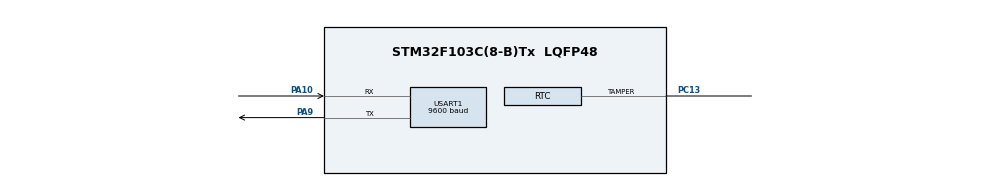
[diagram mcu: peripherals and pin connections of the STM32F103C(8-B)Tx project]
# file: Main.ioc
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Mcu.Family=STM32F1
Mcu.Name=STM32F103C(8-B)Tx
Mcu.Package=LQFP48
NVIC.PriorityGroup=NVIC_PRIORITYGROUP_4
NVIC.RTC_IRQn=true\:0\:0\:false\:false\:true\:true\:true\:true
NVIC.TAMPER_IRQn=true\:0\:0\:false\:false\:true\:true\:true\:true
PA10.Mode=Asynchronous
PA10.Signal=USART1_RX
PA13.Mode=Serial_Wire
PA13.Signal=SYS_JTMS-SWDIO
PA14.Mode=Serial_Wire
PA14.Signal=SYS_JTCK-SWCLK
PA9.Mode=Asynchronous
PA9.Signal=USART1_TX
PC13-TAMPER-RTC.Mode=Tamper
PC13-TAMPER-RTC.Signal=RTC_TAMPER
PC14-OSC32_IN.Mode=LSE-External-Oscillator
PC14-OSC32_IN.Signal=RCC_OSC32_IN
PC15-OSC32_OUT.Mode=LSE-External-Oscillator
PC15-OSC32_OUT.Signal=RCC_OSC32_OUT
ProjectManager.HeapSize=0x200
ProjectManager.StackSize=0x400
ProjectManager.TargetToolchain=MDK-ARM V5.32
RCC.AHBFreq_Value=8000000
RCC.APB1Freq_Value=8000000
RCC.APB1TimFreq_Value=8000000
RCC.APB2Freq_Value=8000000
RCC.APB2TimFreq_Value=8000000
RCC.HCLKFreq_Value=8000000
RCC.PLLMUL=RCC_PLL_MUL9
RCC.RTCClockSelection=RCC_RTCCLKSOURCE_LSE
RCC.SYSCLKFreq_VALUE=8000000
RCC.USBFreq_Value=36000000
RTC.AutoPrediv=RTC_AUTO_1_SECOND
RTC.Format=RTC_FORMAT_BIN
RTC.OutPut=RTC_OUTPUTSOURCE_NONE
USART1.BaudRate=9600
USART1.VirtualMode=VM_ASYNC
VP_RTC_VS_RTC_Activate.Mode=RTC_Enabled
VP_RTC_VS_RTC_Calendar.Mode=RTC_Calendar
board=custom

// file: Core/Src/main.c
/* USER CODE BEGIN Header */
/**
  ******************************************************************************
  * @file           : main.c
  * @brief          : Main program body
  ******************************************************************************
  * @attention
  *
  * <h2><center>&copy; Copyright (c) 2021 STMicroelectronics.
  * All rights reserved.</center></h2>
  *
  * This software component is licensed by ST under BSD 3-Clause license,
  * the "License"; You may not use this file except in compliance with the
  * License. You may obtain a copy of the License at:
  *                        opensource.org/licenses/BSD-3-Clause
  *
  ******************************************************************************
  */
/* USER CODE END Header */
#include "main.h"

/* USER CODE BEGIN Includes */
#include "stdio.h"
/* USER CODE END Includes */

/* USER CODE BEGIN PV */
uint32_t buffer=0;
/* USER CODE END PV */

void SystemClock_Config(void);
static void MX_GPIO_Init(void);
static void MX_RTC_Init(void);
static void MX_USART1_UART_Init(void);

/* USER CODE BEGIN 0 */
/* Function for transmitting 8bit data via USART */
void write_uart(char data){
	while(!LL_USART_IsActiveFlag_TXE(USART1));
	LL_USART_TransmitData8(USART1, (uint8_t)data);
}

/* Retargeting stdout_putchar as to use USART_TX for data output */
int stdout_putchar(int ch){
	write_uart(ch);
	return (ch);
}

struct time_t
{
  uint8_t sec;
  uint8_t min;
  uint8_t hour;
};

struct time_t Time;
struct time_t Alarm;

uint32_t TimeCounter = 0;

void TIME_Update(void);
void TIME_Config(uint8_t, uint8_t, uint8_t);
void ALARM_Config(uint8_t, uint8_t, uint8_t);
/* USER CODE END 0 */

int main(void)
{

  /* MCU Configuration--------------------------------------------------------*/

  /* Reset of all peripherals, Initializes the Flash interface and the Systick. */
  LL_APB2_GRP1_EnableClock(LL_APB2_GRP1_PERIPH_AFIO);
  LL_APB1_GRP1_EnableClock(LL_APB1_GRP1_PERIPH_PWR);

  /* System interrupt init*/
  NVIC_SetPriorityGrouping(NVIC_PRIORITYGROUP_4);

  /** NOJTAG: JTAG-DP Disabled and SW-DP Enabled
  */
  LL_GPIO_AF_Remap_SWJ_NOJTAG();

  /* Configure the system clock */
  SystemClock_Config();

  /* Initialize all configured peripherals */
  MX_GPIO_Init();
  MX_RTC_Init();
  MX_USART1_UART_Init();
	printf("TEST USART1 \r\n");
  /* USER CODE BEGIN 2 */
  /* configue date, time and alarm and also enabling alarm interrupt */
	LL_RTC_DisableWriteProtection(RTC);
  LL_RTC_EnterInitMode(RTC);
	LL_RTC_EnableIT_ALR(RTC);
	LL_RTC_ClearFlag_ALR(RTC);
//	LL_EXTI_EnableIT_0_31(LL_EXTI_LINE_17);
//	LL_EXTI_EnableRisingTrig_0_31(LL_EXTI_LINE_17);
//
	LL_RTC_ExitInitMode(RTC);
	LL_RTC_EnableWriteProtection(RTC);
  /* USER CODE END 2 */

  /* Infinite loop */
  /* USER CODE BEGIN WHILE */

	TIME_Config(23, 59, 55);
	ALARM_Config(00, 00, 05);

	//printf("GetRTCClockSource: %.2d\r\n", buffer);

  while(1){
    /* USER CODE END WHILE */

    /* USER CODE BEGIN 3 */
		/* update and print date and time */
		for(int i=0; i<10; i++){
			TIME_Update();
			printf("Time: %.2d:%.2d:%.2d\r\n", Time.hour, Time.min, Time.sec);
			LL_mDelay(998);
		}
  }
  /* USER CODE END 3 */
}

void SystemClock_Config(void)
{
  LL_FLASH_SetLatency(LL_FLASH_LATENCY_0);
  while(LL_FLASH_GetLatency()!= LL_FLASH_LATENCY_0)
  {
  }
  LL_RCC_HSI_SetCalibTrimming(16);
  LL_RCC_HSI_Enable();

   /* Wait till HSI is ready */
  while(LL_RCC_HSI_IsReady() != 1)
  {

  }
  LL_PWR_EnableBkUpAccess();
  if(LL_RCC_GetRTCClockSource() != LL_RCC_RTC_CLKSOURCE_LSE)
  {
    LL_RCC_ForceBackupDomainReset();
    LL_RCC_ReleaseBackupDomainReset();
  }
  LL_RCC_LSE_Enable();

   /* Wait till LSE is ready */
  while(LL_RCC_LSE_IsReady() != 1)
  {

  }
  if(LL_RCC_GetRTCClockSource() != LL_RCC_RTC_CLKSOURCE_LSE)
  {
    LL_RCC_SetRTCClockSource(LL_RCC_RTC_CLKSOURCE_LSE);
  }
  LL_RCC_EnableRTC();
  LL_RCC_SetAHBPrescaler(LL_RCC_SYSCLK_DIV_1);
  LL_RCC_SetAPB1Prescaler(LL_RCC_APB1_DIV_1);
  LL_RCC_SetAPB2Prescaler(LL_RCC_APB2_DIV_1);
  LL_RCC_SetSysClkSource(LL_RCC_SYS_CLKSOURCE_HSI);

   /* Wait till System clock is ready */
  while(LL_RCC_GetSysClkSource() != LL_RCC_SYS_CLKSOURCE_STATUS_HSI)
  {

  }
  LL_Init1msTick(8000000);
  LL_SetSystemCoreClock(8000000);
}

static void MX_RTC_Init(void)
{

  LL_RTC_InitTypeDef RTC_InitStruct = {0};
  LL_RTC_TimeTypeDef RTC_TimeStruct = {0};

    LL_PWR_EnableBkUpAccess();
    /* Enable BKP CLK enable for backup registers */
    LL_APB1_GRP1_EnableClock(LL_APB1_GRP1_PERIPH_BKP);
  /* Peripheral clock enable */
  LL_RCC_EnableRTC();

  /* RTC interrupt Init */
  NVIC_SetPriority(TAMPER_IRQn, NVIC_EncodePriority(NVIC_GetPriorityGrouping(),0, 0));
  NVIC_EnableIRQ(TAMPER_IRQn);
  NVIC_SetPriority(RTC_IRQn, NVIC_EncodePriority(NVIC_GetPriorityGrouping(),0, 0));
  NVIC_EnableIRQ(RTC_IRQn);

  /** Initialize RTC and set the Time and Date
  */
  RTC_InitStruct.AsynchPrescaler = 0xFFFFFFFFU;
  LL_RTC_Init(RTC, &RTC_InitStruct);
  LL_RTC_SetAsynchPrescaler(RTC, 0xFFFFFFFFU);

  /** Initialize RTC and set the Time and Date
  */
  RTC_TimeStruct.Hours = 0;
  RTC_TimeStruct.Minutes = 0;
  RTC_TimeStruct.Seconds = 0;
  LL_RTC_TIME_Init(RTC, LL_RTC_FORMAT_BIN, &RTC_TimeStruct);

  /** Initialize RTC and set the Time and Date
  */
  /* USER CODE BEGIN RTC_Init 2 */
  /* set RTC clock prescaler to 32768 (8000-1 hex)*/
  RTC_InitStruct.AsynchPrescaler = 0x00007FFFU;
  LL_RTC_Init(RTC, &RTC_InitStruct);
  LL_RTC_SetAsynchPrescaler(RTC, 0x00007FFFU);
  /* USER CODE END RTC_Init 2 */

}

static void MX_USART1_UART_Init(void)
{

  LL_USART_InitTypeDef USART_InitStruct = {0};

  LL_GPIO_InitTypeDef GPIO_InitStruct = {0};

  /* Peripheral clock enable */
  LL_APB2_GRP1_EnableClock(LL_APB2_GRP1_PERIPH_USART1);

  LL_APB2_GRP1_EnableClock(LL_APB2_GRP1_PERIPH_GPIOA);
  /**USART1 GPIO Configuration
  PA9   ------> USART1_TX
  PA10   ------> USART1_RX
  */
  GPIO_InitStruct.Pin = LL_GPIO_PIN_9;
  GPIO_InitStruct.Mode = LL_GPIO_MODE_ALTERNATE;
  GPIO_InitStruct.Speed = LL_GPIO_SPEED_FREQ_HIGH;
  GPIO_InitStruct.OutputType = LL_GPIO_OUTPUT_PUSHPULL;
  LL_GPIO_Init(GPIOA, &GPIO_InitStruct);

  GPIO_InitStruct.Pin = LL_GPIO_PIN_10;
  GPIO_InitStruct.Mode = LL_GPIO_MODE_FLOATING;
  LL_GPIO_Init(GPIOA, &GPIO_InitStruct);

  USART_InitStruct.BaudRate = 9600;
  USART_InitStruct.DataWidth = LL_USART_DATAWIDTH_8B;
  USART_InitStruct.StopBits = LL_USART_STOPBITS_1;
  USART_InitStruct.Parity = LL_USART_PARITY_NONE;
  USART_InitStruct.TransferDirection = LL_USART_DIRECTION_TX_RX;
  USART_InitStruct.HardwareFlowControl = LL_USART_HWCONTROL_NONE;
  USART_InitStruct.OverSampling = LL_USART_OVERSAMPLING_16;
  LL_USART_Init(USART1, &USART_InitStruct);
  LL_USART_ConfigAsyncMode(USART1);
  LL_USART_Enable(USART1);

}

static void MX_GPIO_Init(void)
{

  /* GPIO Ports Clock Enable */
  LL_APB2_GRP1_EnableClock(LL_APB2_GRP1_PERIPH_GPIOC);
  LL_APB2_GRP1_EnableClock(LL_APB2_GRP1_PERIPH_GPIOA);

}

/* USER CODE BEGIN 4 */
//*****************************************************************
void TIME_Update(void)
{
  TimeCounter = LL_RTC_TIME_Get(RTC);
  Time.hour = (TimeCounter/3600) % 24;
  Time.min  = (TimeCounter % 3600) / 60;
  Time.sec  = (TimeCounter % 3600) % 60;
}

//*****************************************************************
void TIME_Config(uint8_t fHour, uint8_t fMin, uint8_t fSec){
  Time.hour = fHour;
  Time.min  = fMin;
  Time.sec  = fSec;

	LL_RTC_DisableWriteProtection(RTC);
  LL_RTC_EnterInitMode(RTC);

	LL_RTC_TIME_Set(RTC,((Time.hour * 3600) +
                       (Time.min * 60) +
                        Time.sec));

	LL_RTC_ExitInitMode(RTC);
	LL_RTC_EnableWriteProtection(RTC);
}

//*****************************************************************
void ALARM_Config(uint8_t fHour, uint8_t fMin, uint8_t fSec){
  Alarm.hour = fHour;
  Alarm.min  = fMin;
  Alarm.sec  = fSec;

	LL_RTC_DisableWriteProtection(RTC);
  LL_RTC_EnterInitMode(RTC);

  LL_RTC_ALARM_Set(RTC,((Alarm.hour * 3600) +
                        (Alarm.min * 60) +
                         Alarm.sec));

	LL_RTC_ExitInitMode(RTC);
	LL_RTC_EnableWriteProtection(RTC);
}
/* USER CODE END 4 */

void Error_Handler(void)
{
  __disable_irq();
  while (1)
  {
  }
}
